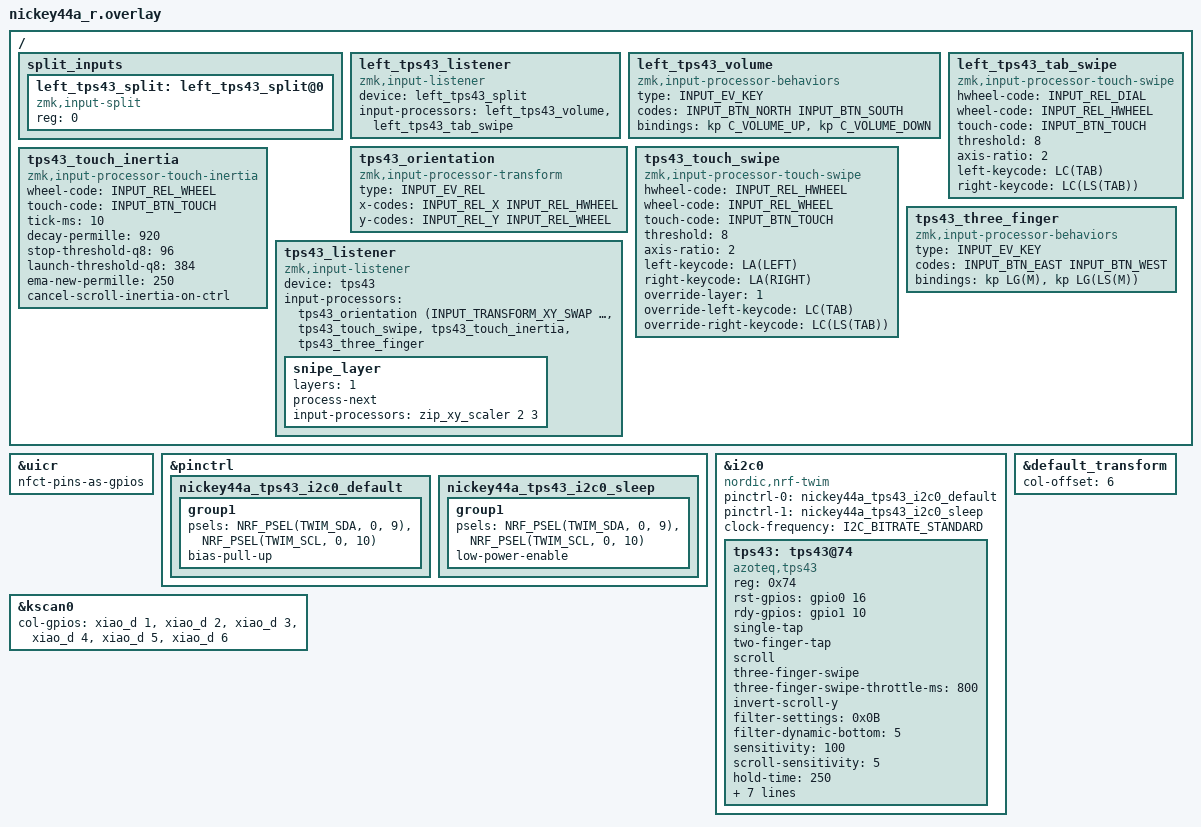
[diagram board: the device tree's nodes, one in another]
#include "nickey44a.dtsi"
#include <input/processors.dtsi>
#include <dt-bindings/pinctrl/nrf-pinctrl.h>
#include <dt-bindings/zmk/input_transform.h>
#include <dt-bindings/zmk/keys.h>
#include <zephyr/dt-bindings/input/input-event-codes.h>

/*
 * TPS43 FPC breakout wiring:
 *   SDA = XIAO NFC1/P0.09
 *   SCL = XIAO NFC2/P0.10
 *   RDY = XIAO P1.10
 *   NRST = XIAO P0.16
 */

&uicr {
    nfct-pins-as-gpios;
};

&pinctrl {
    nickey44a_tps43_i2c0_default: nickey44a_tps43_i2c0_default {
        group1 {
            psels = <NRF_PSEL(TWIM_SDA, 0, 9)>,
                    <NRF_PSEL(TWIM_SCL, 0, 10)>;
            /* The TPS43 breakout has no I2C pull-up resistors. */
            bias-pull-up;
        };
    };

    nickey44a_tps43_i2c0_sleep: nickey44a_tps43_i2c0_sleep {
        group1 {
            psels = <NRF_PSEL(TWIM_SDA, 0, 9)>,
                    <NRF_PSEL(TWIM_SCL, 0, 10)>;
            low-power-enable;
        };
    };
};

/ {
    split_inputs {
        #address-cells = <1>;
        #size-cells = <0>;

        left_tps43_split: left_tps43_split@0 {
            compatible = "zmk,input-split";
            reg = <0>;
        };
    };

    left_tps43_listener: left_tps43_listener {
        compatible = "zmk,input-listener";
        device = <&left_tps43_split>;
        input-processors = <&left_tps43_volume>, <&left_tps43_tab_swipe>;
    };

    /* Left pad one-finger flick: up = volume up, down = volume down.
     * Left/right flick events are left unmapped and ignored. */
    left_tps43_volume: left_tps43_volume {
        compatible = "zmk,input-processor-behaviors";
        #input-processor-cells = <0>;
        type = <INPUT_EV_KEY>;
        codes = <INPUT_BTN_NORTH INPUT_BTN_SOUTH>;
        bindings = <&kp C_VOLUME_UP>, <&kp C_VOLUME_DOWN>;
    };

    left_tps43_tab_swipe: left_tps43_tab_swipe {
        compatible = "zmk,input-processor-touch-swipe";
        #input-processor-cells = <0>;
        hwheel-code = <INPUT_REL_DIAL>;
        wheel-code = <INPUT_REL_HWHEEL>;
        touch-code = <INPUT_BTN_TOUCH>;
        threshold = <8>;
        axis-ratio = <2>;
        /* Measured left pad: physical right swipe produces negative DIAL. */
        left-keycode = <LC(TAB)>;
        right-keycode = <LC(LS(TAB))>;
    };

    tps43_orientation: tps43_orientation {
        compatible = "zmk,input-processor-transform";
        #input-processor-cells = <1>;
        type = <INPUT_EV_REL>;
        x-codes = <INPUT_REL_X INPUT_REL_HWHEEL>;
        y-codes = <INPUT_REL_Y INPUT_REL_WHEEL>;
    };

    tps43_touch_swipe: tps43_touch_swipe {
        compatible = "zmk,input-processor-touch-swipe";
        #input-processor-cells = <0>;
        hwheel-code = <INPUT_REL_HWHEEL>;
        wheel-code = <INPUT_REL_WHEEL>;
        touch-code = <INPUT_BTN_TOUCH>;
        threshold = <8>;
        axis-ratio = <2>;
        /* Alt+Left/Right: browser back/forward that also works on Windows. */
        left-keycode = <LA(LEFT)>;
        right-keycode = <LA(RIGHT)>;
        override-layer = <1>;
        /* Physical right swipe is negative after orientation correction. */
        override-left-keycode = <LC(TAB)>;
        override-right-keycode = <LC(LS(TAB))>;
    };

    tps43_touch_inertia: tps43_touch_inertia {
        compatible = "zmk,input-processor-touch-inertia";
        #input-processor-cells = <0>;
        wheel-code = <INPUT_REL_WHEEL>;
        touch-code = <INPUT_BTN_TOUCH>;
        tick-ms = <10>;
        decay-permille = <920>;
        stop-threshold-q8 = <96>;
        launch-threshold-q8 = <384>;
        ema-new-permille = <250>;
        cancel-scroll-inertia-on-ctrl;
    };

    /* Right pad three-finger swipe. The driver reports it in controller
     * coordinates, before the orientation transform below: physical up is
     * BTN_EAST and physical down is BTN_WEST. Left/right are unmapped. */
    tps43_three_finger: tps43_three_finger {
        compatible = "zmk,input-processor-behaviors";
        #input-processor-cells = <0>;
        type = <INPUT_EV_KEY>;
        codes = <INPUT_BTN_EAST INPUT_BTN_WEST>;
        bindings = <&kp LG(M)>, <&kp LG(LS(M))>;
    };

    tps43_listener: tps43_listener {
        compatible = "zmk,input-listener";
        device = <&tps43>;
        /* Correct the measured controller output: left -> down, down -> left. */
        input-processors = <&tps43_orientation (INPUT_TRANSFORM_XY_SWAP |
                                             INPUT_TRANSFORM_X_INVERT |
                                             INPUT_TRANSFORM_Y_INVERT)>,
                           <&tps43_touch_swipe>, <&tps43_touch_inertia>,
                           <&tps43_three_finger>;

        snipe_layer {
            layers = <1>;
            process-next;
            input-processors = <&zip_xy_scaler 2 3>;
        };
    };
};

&i2c0 {
    status = "okay";
    compatible = "nordic,nrf-twim";
    pinctrl-0 = <&nickey44a_tps43_i2c0_default>;
    pinctrl-1 = <&nickey44a_tps43_i2c0_sleep>;
    pinctrl-names = "default", "sleep";
    clock-frequency = <I2C_BITRATE_STANDARD>;
    #address-cells = <1>;
    #size-cells = <0>;

    tps43: tps43@74 {
        compatible = "azoteq,tps43";
        reg = <0x74>;
        rst-gpios = <&gpio0 16 GPIO_ACTIVE_HIGH>;
        rdy-gpios = <&gpio1 10 GPIO_ACTIVE_HIGH>;

        single-tap;
        two-finger-tap;
        scroll;
        /* Three-finger swipe: up/down = minimize/restore all windows. */
        three-finger-swipe;
        /* One action per swipe: ignore repeats within 0.8 s. */
        three-finger-swipe-throttle-ms = <800>;
        /* The listener swaps axes, so driver X controls host vertical scrolling. */
        invert-scroll-y;

        filter-settings = <0x0B>;
        filter-dynamic-bottom = <5>;
        sensitivity = <100>;
        scroll-sensitivity = <5>;
        hold-time = <250>;
        enable-power-management;
        /* Faster first-touch response: keep idle/low-power scan intervals short.
         * Costs some battery while the keyboard is awake. */
        report-rate-idle-touch = <10>;
        report-rate-idle = <10>;
        report-rate-lp1 = <20>;
        report-rate-lp2 = <40>;
        /* Controller settings used when the listener's correction was measured. */
        switch-xy;
        invert-x;
    };
};

&default_transform {
    col-offset = <6>;
};

&kscan0 {
        col-gpios
            = <&xiao_d 1 GPIO_ACTIVE_HIGH>
            , <&xiao_d 2 GPIO_ACTIVE_HIGH>
            , <&xiao_d 3 GPIO_ACTIVE_HIGH>
            , <&xiao_d 4 GPIO_ACTIVE_HIGH>
            , <&xiao_d 5 GPIO_ACTIVE_HIGH>
            , <&xiao_d 6 GPIO_ACTIVE_HIGH>
            ;
};
